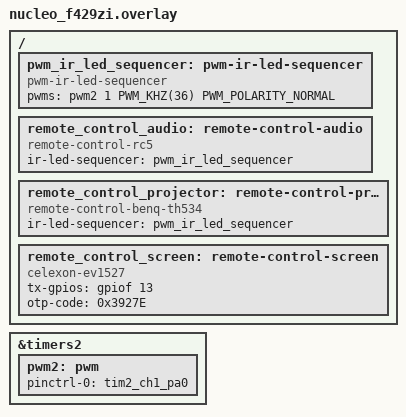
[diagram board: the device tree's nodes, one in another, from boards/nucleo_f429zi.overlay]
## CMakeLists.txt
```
cmake_minimum_required(VERSION 3.13.1)
find_package(Zephyr REQUIRED HINTS $ENV{ZEPHYR_BASE})

project(app LANGUAGES C CXX)

target_sources(app PRIVATE src/main.cpp)
```

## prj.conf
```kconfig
CONFIG_CPP=y

CONFIG_REMOTE_CONTROL=y
#CONFIG_GLIBCXX_LIBCPP=y
CONFIG_LED=y
CONFIG_LOG=y
CONFIG_REMOTE_CONTROL_LOG_LEVEL_DBG=y
CONFIG_IR_LED_SEQUENCER_LOG_LEVEL_DBG=y
```

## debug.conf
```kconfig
# This is a Kconfig fragment which can be used to enable debug-related options
# in the application. See the README for more details.

# compiler
CONFIG_DEBUG_OPTIMIZATIONS=y

# logging
CONFIG_LOG=y
CONFIG_APP_LOG_LEVEL_DBG=y
CONFIG_REMOTE_CONTROL_LOG_LEVEL_DBG=y
```

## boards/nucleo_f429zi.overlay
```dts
/ {
	pwm_ir_led_sequencer: pwm-ir-led-sequencer {
		compatible = "pwm-ir-led-sequencer";
		pwms = <&pwm2 1 PWM_KHZ(36) PWM_POLARITY_NORMAL>;
	};

	remote_control_audio: remote-control-audio {
		compatible = "remote-control-rc5";
		
		ir-led-sequencer = <&pwm_ir_led_sequencer>;
	};

	remote_control_projector: remote-control-projector {
		compatible = "remote-control-benq-th534";

		ir-led-sequencer = <&pwm_ir_led_sequencer>;
	};

	remote_control_screen: remote-control-screen {
		compatible = "celexon-ev1527";
		tx-gpios = <&gpiof 13 GPIO_ACTIVE_HIGH>;
		otp-code = <0x3927E>;
	};
};

&timers2 {
	status = "okay";
	//st,prescaler = <10000>;

	pwm2: pwm {
		status = "okay";
        pinctrl-0 = <&tim2_ch1_pa0>;
		pinctrl-names = "default";
	};
};
```

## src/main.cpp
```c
#include "zephyr/device.h"
#include "zephyr/sys/printk.h"
#include <zephyr/kernel.h>
#include <zephyr/logging/log.h>

#include <drivers/remote_control.h>
#include <zephyr/drivers/led.h>

#include <app_version.h>

LOG_MODULE_REGISTER(main, CONFIG_APP_LOG_LEVEL);

int main()
{
	printk("Zephyr Example Application %s\n", APP_VERSION_STRING);

	const struct device* audio = DEVICE_DT_GET(DT_NODELABEL(remote_control_audio));
	const struct device* projector = DEVICE_DT_GET(DT_NODELABEL(remote_control_projector));
	const struct device* screen = DEVICE_DT_GET(DT_NODELABEL(remote_control_screen));


	if (!device_is_ready(audio)) {
		LOG_ERR("Audio not ready");
		return 0;
	}

	if (!device_is_ready(projector)) {
		LOG_ERR("Projector not ready");
		return 0;
	}

	if (!device_is_ready(screen)) {
		LOG_ERR("Screen not ready");
		return 0;
	}

	const struct device* led = DEVICE_DT_GET(DT_NODELABEL(leds));
	if (!device_is_ready(led)) {
		LOG_ERR("LED not ready");
		return 0;
	}


	while (1) {
		led_on(led, 0);
		k_sleep(K_MSEC(500));
		led_off(led, 0);

		k_sleep(K_MSEC(10000));
		
		remote_control_press_button(audio, REMOTE_CONTROL_BUTTON_POWER);
		remote_control_press_button(projector, REMOTE_CONTROL_BUTTON_POWER);
		remote_control_press_button(screen, REMOTE_CONTROL_BUTTON_DOWN);

		k_sleep(K_MSEC(5000));
	}

	return 0;
}
```
